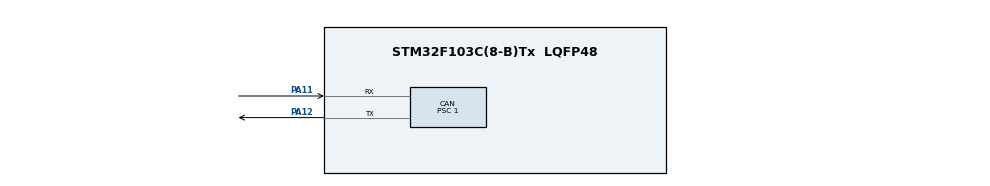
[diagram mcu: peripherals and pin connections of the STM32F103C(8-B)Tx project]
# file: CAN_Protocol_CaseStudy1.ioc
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CAN.BS1=CAN_BS1_6TQ
CAN.CalculateTimeBit=1000
CAN.CalculateTimeQuantum=125.0
CAN.Mode=CAN_MODE_LOOPBACK
CAN.Prescaler=1
Mcu.Family=STM32F1
Mcu.Name=STM32F103C(8-B)Tx
Mcu.Package=LQFP48
NVIC.PriorityGroup=NVIC_PRIORITYGROUP_4
PA11.Mode=Master
PA11.Signal=CAN_RX
PA12.Mode=Master
PA12.Signal=CAN_TX
PA13.Mode=Serial_Wire
PA13.Signal=SYS_JTMS-SWDIO
PA14.Mode=Serial_Wire
PA14.Signal=SYS_JTCK-SWCLK
ProjectManager.HeapSize=0x200
ProjectManager.StackSize=0x400
ProjectManager.TargetToolchain=STM32CubeIDE
RCC.APB1Freq_Value=8000000
RCC.APB2Freq_Value=8000000
board=custom

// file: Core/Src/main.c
/* USER CODE BEGIN Header */
/**
 ******************************************************************************
 * @file           : main.c
 * @brief          : Main program body
 ******************************************************************************
 * @attention
 *
 * <h2><center>&copy; Copyright (c) 2024 STMicroelectronics.
 * All rights reserved.</center></h2>
 *
 * This software component is licensed by ST under BSD 3-Clause license,
 * the "License"; You may not use this file except in compliance with the
 * License. You may obtain a copy of the License at:
 *                        opensource.org/licenses/BSD-3-Clause
 *
 ******************************************************************************
 */
/* USER CODE END Header */
#include "main.h"

CAN_HandleTypeDef hcan;

void SystemClock_Config(void);
static void MX_GPIO_Init(void);
static void MX_CAN_Init(void);

void CAN_Tx(uint32_t ID, uint8_t DLC, char *TxData)
{
	//	(#) To manage messages transmission, the following Tx control functions
	//			can be used:
	//			(++) HAL_CAN_AddTxMessage() to request transmission of a new
	//			message.
	//			(++) HAL_CAN_AbortTxRequest() to abort transmission of a pending
	//			message.
	//			(++) HAL_CAN_GetTxMailboxesFreeLevel() to get the number of free Tx
	//			mailboxes.
	//			(++) HAL_CAN_IsTxMessagePending() to check if a message is pending
	//			in a Tx mailbox.
	//			(++) HAL_CAN_GetTxTimestamp() to get the timestamp of Tx message
	//			sent, if time triggered communication mode is enabled.
	//    (#) Transmission:
	//          (++) Monitor the Tx mailboxes availability until at least one Tx
	//               mailbox is free, using HAL_CAN_GetTxMailboxesFreeLevel().
	//          (++) Then request transmission of a message using
	//               HAL_CAN_AddTxMessage().

	uint8_t No_Free_MailBoxes;
	No_Free_MailBoxes = HAL_CAN_GetTxMailboxesFreeLevel(&hcan);

	CAN_TxHeaderTypeDef pHeader;
	pHeader.DLC = DLC;
	pHeader.IDE = CAN_ID_STD;
	pHeader.RTR = CAN_RTR_DATA;
	pHeader.StdId = ID;

	uint32_t TxMailbox = 0;

	if(No_Free_MailBoxes)
	{
		if(HAL_CAN_AddTxMessage(&hcan, &pHeader, TxData, &TxMailbox) != HAL_OK)
		{
			Error_Handler();
		}

		while(HAL_CAN_IsTxMessagePending(&hcan, TxMailbox)); //wait until transmission
	}
}

void Configure_FilterBank(uint8_t No_FilerBank, uint32_t ID, uint32_t Mask)
{
	//    (#) Configure the reception filters using the following configuration functions:
	//          (++) HAL_CAN_ConfigFilter()
	CAN_FilterTypeDef sFilterConfig;
	sFilterConfig.FilterActivation = CAN_FILTER_ENABLE;
	sFilterConfig.FilterBank = No_FilerBank;
	sFilterConfig.FilterFIFOAssignment = CAN_FILTER_FIFO0;
	sFilterConfig.FilterIdHigh = (ID << 5);
	sFilterConfig.FilterIdLow = 0x0000;
	sFilterConfig.FilterMaskIdHigh = (Mask << 5);
	sFilterConfig.FilterMaskIdLow = 0x0000;
	sFilterConfig.FilterMode = CAN_FILTERMODE_IDMASK;
	sFilterConfig.FilterScale = CAN_FILTERSCALE_32BIT;

	if(HAL_CAN_ConfigFilter(&hcan, &sFilterConfig) != HAL_OK)
	{
		Error_Handler();
	}
}

void CAN_Rx(uint32_t *ID, uint8_t *DLC, char *RxData)
{
	//    (#) When a message is received into the CAN Rx FIFOs, it can be retrieved
	//        using the HAL_CAN_GetRxMessage() function. The function
	//        HAL_CAN_GetRxFifoFillLevel() allows to know how many Rx message are
	//        stored in the Rx Fifo.
	//    (#) Reception:
	//          (++) Monitor reception of message using HAL_CAN_GetRxFifoFillLevel()
	//               until at least one message is received.
	//          (++) Then get the message using HAL_CAN_GetRxMessage().
	CAN_RxHeaderTypeDef pHeader;

	while(HAL_CAN_GetRxFifoFillLevel(&hcan, CAN_FILTER_FIFO0) == 0);

	if(HAL_CAN_GetRxMessage(&hcan, CAN_FILTER_FIFO0, &pHeader, RxData) != HAL_OK)
	{
		Error_Handler();
	}

	*ID = pHeader.StdId;
	*DLC = pHeader.DLC;
}

int main(void)
{

	/* MCU Configuration--------------------------------------------------------*/

	/* Reset of all peripherals, Initializes the Flash interface and the Systick. */
	HAL_Init();

	/* Configure the system clock */
	SystemClock_Config();

	/* Initialize all configured peripherals */
	MX_GPIO_Init();
	MX_CAN_Init();

	//    (#) Configure the reception filters using the following configuration functions:
	//          (++) HAL_CAN_ConfigFilter()
	Configure_FilterBank(0, 0x710, 0x7FF);

	//  (#) Start the CAN module using HAL_CAN_Start() function. At this level
	//      the node is active on the bus: it receive messages, and can send messages.
	// CAN (Initialization) --> CAN (Running)
	if(HAL_CAN_Start(&hcan) != HAL_OK)
	{
		Error_Handler();
	}

	char DataTx[8] = {'A', 'B', 'C', 'D', 'E', 'F', 'G', '#'};
	char Frame_No = 0;
	uint32_t Rx_ID, Rx_DLC;
	char DataRx[8];

	/* Infinite loop */
	/* USER CODE BEGIN WHILE */
	while (1)
	{
		DataTx[7] = Frame_No++;
		CAN_Tx(0x310, 8, DataTx);

		CAN_Rx(&Rx_ID, &Rx_DLC, DataRx);
		/* USER CODE END WHILE */

	}
}

void SystemClock_Config(void)
{
	RCC_OscInitTypeDef RCC_OscInitStruct = {0};
	RCC_ClkInitTypeDef RCC_ClkInitStruct = {0};

	/** Initializes the RCC Oscillators according to the specified parameters
	 * in the RCC_OscInitTypeDef structure.
	 */
	RCC_OscInitStruct.OscillatorType = RCC_OSCILLATORTYPE_HSI;
	RCC_OscInitStruct.HSIState = RCC_HSI_ON;
	RCC_OscInitStruct.HSICalibrationValue = RCC_HSICALIBRATION_DEFAULT;
	RCC_OscInitStruct.PLL.PLLState = RCC_PLL_NONE;
	if (HAL_RCC_OscConfig(&RCC_OscInitStruct) != HAL_OK)
	{
		Error_Handler();
	}
	/** Initializes the CPU, AHB and APB buses clocks
	 */
	RCC_ClkInitStruct.ClockType = RCC_CLOCKTYPE_HCLK|RCC_CLOCKTYPE_SYSCLK
			|RCC_CLOCKTYPE_PCLK1|RCC_CLOCKTYPE_PCLK2;
	RCC_ClkInitStruct.SYSCLKSource = RCC_SYSCLKSOURCE_HSI;
	RCC_ClkInitStruct.AHBCLKDivider = RCC_SYSCLK_DIV1;
	RCC_ClkInitStruct.APB1CLKDivider = RCC_HCLK_DIV1;
	RCC_ClkInitStruct.APB2CLKDivider = RCC_HCLK_DIV1;

	if (HAL_RCC_ClockConfig(&RCC_ClkInitStruct, FLASH_LATENCY_0) != HAL_OK)
	{
		Error_Handler();
	}
}

static void MX_CAN_Init(void)
{

	hcan.Instance = CAN1;
	hcan.Init.Prescaler = 1;
	hcan.Init.Mode = CAN_MODE_LOOPBACK;
	hcan.Init.SyncJumpWidth = CAN_SJW_1TQ;
	hcan.Init.TimeSeg1 = CAN_BS1_6TQ;
	hcan.Init.TimeSeg2 = CAN_BS2_1TQ;
	hcan.Init.TimeTriggeredMode = DISABLE;
	hcan.Init.AutoBusOff = DISABLE;
	hcan.Init.AutoWakeUp = DISABLE;
	hcan.Init.AutoRetransmission = ENABLE;
	hcan.Init.ReceiveFifoLocked = DISABLE;
	hcan.Init.TransmitFifoPriority = DISABLE;
	if (HAL_CAN_Init(&hcan) != HAL_OK)
	{
		Error_Handler();
	}

}

static void MX_GPIO_Init(void)
{

	/* GPIO Ports Clock Enable */
	__HAL_RCC_GPIOA_CLK_ENABLE();

}

void Error_Handler(void)
{
}

/************************ (C) COPYRIGHT STMicroelectronics *****END OF FILE****/
